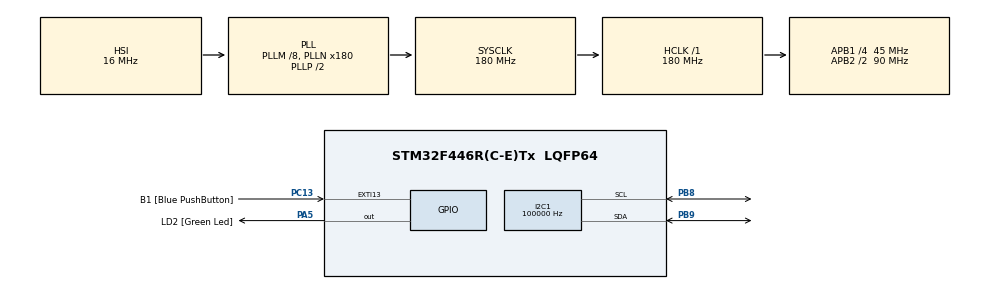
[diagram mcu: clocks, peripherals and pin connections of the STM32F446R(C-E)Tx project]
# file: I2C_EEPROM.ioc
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I2C1.ClockSpeed=100000
I2C1.I2C_Mode=I2C_Standard
Mcu.Family=STM32F4
Mcu.Name=STM32F446R(C-E)Tx
Mcu.Package=LQFP64
NVIC.PriorityGroup=NVIC_PRIORITYGROUP_0
PA13.GPIO_Label=TMS
PA13.Mode=Serial_Wire
PA13.Signal=SYS_JTMS-SWDIO
PA14.GPIO_Label=TCK
PA14.Mode=Serial_Wire
PA14.Signal=SYS_JTCK-SWCLK
PA2.GPIO_Label=USART_TX
PA2.Signal=USART2_TX
PA3.GPIO_Label=USART_RX
PA3.Signal=USART2_RX
PA5.GPIO_Label=LD2 [Green Led]
PA5.Signal=GPIO_Output
PB3.GPIO_Label=SWO
PB3.Signal=SYS_JTDO-SWO
PB8.Mode=I2C
PB8.Signal=I2C1_SCL
PB9.Mode=I2C
PB9.Signal=I2C1_SDA
PC13.GPIO_Label=B1 [Blue PushButton]
PC13.GPIO_ModeDefaultEXTI=GPIO_MODE_IT_FALLING
PC13.Signal=GPXTI13
PC14-OSC32_IN.Signal=RCC_OSC32_IN
PC15-OSC32_OUT.Signal=RCC_OSC32_OUT
PH0-OSC_IN.Mode=HSE-External-Clock-Source
PH0-OSC_IN.Signal=RCC_OSC_IN
PH1-OSC_OUT.Mode=HSE-External-Clock-Source
PH1-OSC_OUT.Signal=RCC_OSC_OUT
ProjectManager.HeapSize=0x200
ProjectManager.StackSize=0x400
ProjectManager.TargetToolchain=STM32CubeIDE
RCC.AHBFreq_Value=180000000
RCC.APB1CLKDivider=RCC_HCLK_DIV4
RCC.APB1Freq_Value=45000000
RCC.APB1TimFreq_Value=90000000
RCC.APB2CLKDivider=RCC_HCLK_DIV2
RCC.APB2Freq_Value=90000000
RCC.APB2TimFreq_Value=180000000
RCC.CortexFreq_Value=180000000
RCC.FLatency-AdvancedSettings=FLASH_LATENCY_5
RCC.HCLKFreq_Value=180000000
RCC.HSE_VALUE=8000000
RCC.HSI_VALUE=16000000
RCC.LSE_VALUE=32768
RCC.PLLM=8
RCC.PLLN=180
RCC.SYSCLKFreq_VALUE=180000000
RCC.SYSCLKSource=RCC_SYSCLKSOURCE_PLLCLK
RCC.USBFreq_Value=180000000
RCC.VCOOutputFreq_Value=360000000
board=NUCLEO-F446RE

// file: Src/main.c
/* USER CODE BEGIN Header */
/**
  ******************************************************************************
  * @file           : main.c
  * @brief          : Main program body
  ******************************************************************************
  * @attention
  *
  * <h2><center>&copy; Copyright (c) 2019 STMicroelectronics.
  * All rights reserved.</center></h2>
  *
  * This software component is licensed by ST under BSD 3-Clause license,
  * the "License"; You may not use this file except in compliance with the
  * License. You may obtain a copy of the License at:
  *                        opensource.org/licenses/BSD-3-Clause
  *
  ******************************************************************************
  */
/* USER CODE END Header */

#include "main.h"
#include "i2c.h"
#include "gpio.h"
#include "lcd.h"
#include <string.h>
/* USER CODE BEGIN Includes */
#define EEPROM_DEVICE_ADDRESS 0b1010000 << 1

uint8_t buf[256];
uint8_t str[]= "writing to the bytes\n";
uint8_t* uid;
/* USER CODE END Includes */

void SystemClock_Config(void);

int main(void)
{

  /* MCU Configuration--------------------------------------------------------*/

  /* Reset of all peripherals, Initializes the Flash interface and the Systick. */
  HAL_Init();

  /* Configure the system clock */
  SystemClock_Config();

  /* Initialize all configured peripherals */
  MX_GPIO_Init();
  MX_I2C1_Init();
  LCD_Init();
  /* USER CODE BEGIN 2 */
  //I2C_ScanBus();
  /* USER CODE END 2 */

  /* Infinite loop */
  /* USER CODE BEGIN WHILE */
  //writting_config
  if (HAL_I2C_Mem_Write(&hi2c1, EEPROM_DEVICE_ADDRESS , 0x00 , I2C_MEMADD_SIZE_16BIT, str , strlen((char *) str) ,100 )== HAL_OK)
		{
			  LCD_Printf(" written \n");
		  }
  else{
	  LCD_Printf("error in writting");
  }
  //device_verfyinhg
  /* Wait till device ready */
  		while (HAL_I2C_IsDeviceReady(&hi2c1, EEPROM_DEVICE_ADDRESS, 10, 100) != HAL_OK);
  		LCD_Printf("ok\n");
  //reading_verification
  if (HAL_I2C_Mem_Read(&hi2c1, EEPROM_DEVICE_ADDRESS ,0x00 , I2C_MEMADD_SIZE_16BIT, buf, sizeof(buf) ,100 )== HAL_OK){

        	   LCD_Printf(" it has been read \n%s\n", buf );
           }

  while (1)
  {
    /* USER CODE END WHILE */

  }
}

void SystemClock_Config(void)
{
  RCC_OscInitTypeDef RCC_OscInitStruct = {0};
  RCC_ClkInitTypeDef RCC_ClkInitStruct = {0};

  /** Configure the main internal regulator output voltage
  */
  __HAL_RCC_PWR_CLK_ENABLE();
  __HAL_PWR_VOLTAGESCALING_CONFIG(PWR_REGULATOR_VOLTAGE_SCALE1);
  /** Initializes the CPU, AHB and APB busses clocks
  */
  RCC_OscInitStruct.OscillatorType = RCC_OSCILLATORTYPE_HSI;
  RCC_OscInitStruct.HSIState = RCC_HSI_ON;
  RCC_OscInitStruct.HSICalibrationValue = RCC_HSICALIBRATION_DEFAULT;
  RCC_OscInitStruct.PLL.PLLState = RCC_PLL_ON;
  RCC_OscInitStruct.PLL.PLLSource = RCC_PLLSOURCE_HSI;
  RCC_OscInitStruct.PLL.PLLM = 8;
  RCC_OscInitStruct.PLL.PLLN = 180;
  RCC_OscInitStruct.PLL.PLLP = RCC_PLLP_DIV2;
  RCC_OscInitStruct.PLL.PLLQ = 2;
  RCC_OscInitStruct.PLL.PLLR = 2;
  if (HAL_RCC_OscConfig(&RCC_OscInitStruct) != HAL_OK)
  {
    Error_Handler();
  }
  /** Activate the Over-Drive mode
  */
  if (HAL_PWREx_EnableOverDrive() != HAL_OK)
  {
    Error_Handler();
  }
  /** Initializes the CPU, AHB and APB busses clocks
  */
  RCC_ClkInitStruct.ClockType = RCC_CLOCKTYPE_HCLK|RCC_CLOCKTYPE_SYSCLK
                              |RCC_CLOCKTYPE_PCLK1|RCC_CLOCKTYPE_PCLK2;
  RCC_ClkInitStruct.SYSCLKSource = RCC_SYSCLKSOURCE_PLLCLK;
  RCC_ClkInitStruct.AHBCLKDivider = RCC_SYSCLK_DIV1;
  RCC_ClkInitStruct.APB1CLKDivider = RCC_HCLK_DIV4;
  RCC_ClkInitStruct.APB2CLKDivider = RCC_HCLK_DIV2;

  if (HAL_RCC_ClockConfig(&RCC_ClkInitStruct, FLASH_LATENCY_5) != HAL_OK)
  {
    Error_Handler();
  }
}

void Error_Handler(void)
{
}

/************************ (C) COPYRIGHT STMicroelectronics *****END OF FILE****/
